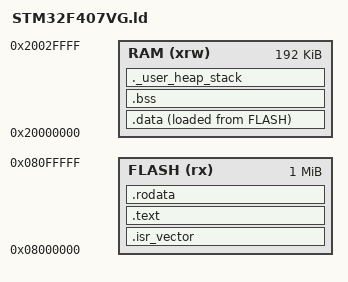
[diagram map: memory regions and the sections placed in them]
/**
 * Linker script for STM32F407VG microcontroller
 * Flash: 1024KB
 * RAM: 192KB
 */

/* Entry point */
ENTRY(Reset_Handler)

/* Highest address of the user mode stack */
_estack = 0x20030000;    /* end of RAM (192K) */

/* Memory areas */
MEMORY
{
  FLASH (rx)      : ORIGIN = 0x08000000, LENGTH = 1024K
  RAM (xrw)       : ORIGIN = 0x20000000, LENGTH = 192K
}

/* Sections */
SECTIONS
{
  /* The startup code goes first into FLASH */
  .isr_vector :
  {
    . = ALIGN(4);
    KEEP(*(.isr_vector))
    . = ALIGN(4);
  } >FLASH

  /* The program code and other data goes into FLASH */
  .text :
  {
    . = ALIGN(4);
    *(.text)
    *(.text*)
    *(.glue_7)
    *(.glue_7t)
    *(.eh_frame)

    KEEP (*(.init))
    KEEP (*(.fini))

    . = ALIGN(4);
    _etext = .;
  } >FLASH

  /* Constant data goes into FLASH */
  .rodata :
  {
    . = ALIGN(4);
    *(.rodata)
    *(.rodata*)
    . = ALIGN(4);
  } >FLASH

  /* Used by the startup to initialize data */
  _sidata = LOADADDR(.data);

  /* Initialized data sections goes into RAM, load LMA copy after code */
  .data :
  {
    . = ALIGN(4);
    _sdata = .;
    *(.data)
    *(.data*)

    . = ALIGN(4);
    _edata = .;
  } >RAM AT> FLASH

  /* Uninitialized data section */
  . = ALIGN(4);
  .bss :
  {
    _sbss = .;
    __bss_start__ = _sbss;
    *(.bss)
    *(.bss*)
    *(COMMON)

    . = ALIGN(4);
    _ebss = .;
    __bss_end__ = _ebss;
  } >RAM

  /* User_heap_stack section, used to check that there is enough RAM left */
  ._user_heap_stack :
  {
    . = ALIGN(8);
    PROVIDE ( end = . );
    PROVIDE ( _end = . );
    . = . + 0x1000;
    . = ALIGN(8);
  } >RAM
}
